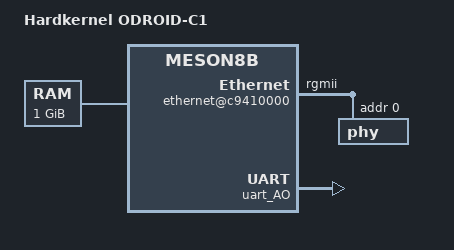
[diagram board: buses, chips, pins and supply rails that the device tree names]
/*
 * Copyright 2014 Beniamino Galvani <b.galvani@gmail.com>
 *
 * This file is dual-licensed: you can use it either under the terms
 * of the GPL or the X11 license, at your option. Note that this dual
 * licensing only applies to this file, and not this project as a
 * whole.
 *
 *  a) This library is free software; you can redistribute it and/or
 *     modify it under the terms of the GNU General Public License as
 *     published by the Free Software Foundation; either version 2 of the
 *     License, or (at your option) any later version.
 *
 *     This library is distributed in the hope that it will be useful,
 *     but WITHOUT ANY WARRANTY; without even the implied warranty of
 *     MERCHANTABILITY or FITNESS FOR A PARTICULAR PURPOSE.  See the
 *     GNU General Public License for more details.
 *
 *     You should have received a copy of the GNU General Public License
 *     along with this program. If not, see <http://www.gnu.org/licenses/>.
 *
 * Or, alternatively,
 *
 *  b) Permission is hereby granted, free of charge, to any person
 *     obtaining a copy of this software and associated documentation
 *     files (the "Software"), to deal in the Software without
 *     restriction, including without limitation the rights to use,
 *     copy, modify, merge, publish, distribute, sublicense, and/or
 *     sell copies of the Software, and to permit persons to whom the
 *     Software is furnished to do so, subject to the following
 *     conditions:
 *
 *     The above copyright notice and this permission notice shall be
 *     included in all copies or substantial portions of the Software.
 *
 *     THE SOFTWARE IS PROVIDED "AS IS", WITHOUT WARRANTY OF ANY KIND,
 *     EXPRESS OR IMPLIED, INCLUDING BUT NOT LIMITED TO THE WARRANTIES
 *     OF MERCHANTABILITY, FITNESS FOR A PARTICULAR PURPOSE AND
 *     NONINFRINGEMENT. IN NO EVENT SHALL THE AUTHORS OR COPYRIGHT
 *     HOLDERS BE LIABLE FOR ANY CLAIM, DAMAGES OR OTHER LIABILITY,
 *     WHETHER IN AN ACTION OF CONTRACT, TORT OR OTHERWISE, ARISING
 *     FROM, OUT OF OR IN CONNECTION WITH THE SOFTWARE OR THE USE OR
 *     OTHER DEALINGS IN THE SOFTWARE.
 */

/dts-v1/;
#include "meson8b.dtsi"

/ {
	model = "Hardkernel ODROID-C1";
	compatible = "hardkernel,odroid-c1", "amlogic,meson8b";

	aliases {
		serial0 = &uart_AO;
	};

	memory {
		reg = <0x00000000 0x40000000>;
	};
};

&uart_AO {
	status = "okay";
};


/ {
	ethernet@c9410000 {
		compatible = "snps,dwmac";
		reg = <0xC9410000 0x2000>;
		interrrupts = <0 8 1>;	/* no 40 */
		interrupt-names = "macirq";
		clocks = <&clk81>;
		clock-names = "stmmaceth";
		mac-address = [00 00 00 00 00 00];/* Filled in by U-Boot */
		snps,multicast-filter-bins = <256>;
		snps,perfect-filter-entries = <128>;

/* per-board setup */
		phy-mode = "rgmii";

		#address-cells = <1>;
		#size-cells = <0>;

		phy: phy@0 {
		     reg = <0>;
	      };

	};
};
